# A31G22x register map
Vendor: ABOV Semiconductor Co., Ltd.; Series: A31G22x; File version: 0.2
CPU: CM0PLUS r0p1, little endian, no MPU, no FPU, VTOR, 2 interrupt priority bits
Registers are 32-bit, read-write, reset 0x0 unless marked. A register's access mark holds for its fields unless they carry their own. Offsets are from the block's base; [hi:lo] are bit positions; {n}, {i} and the like mark numbered series.

## DAC — 12-BIT D/A CONVERTER
Base 0x40003450
0x00 DR — D/A Converter Data Register
  [15:0] DACDR — D/A Converter Data (16-bit) The DACDR[15:0] is a binary format.
0x04 BR ro — D/A Converter Buffer Register
  [15:0] DACBR — D/A Converter Buffer Data (16-bit) The DACBR[15:0] is a binary format.
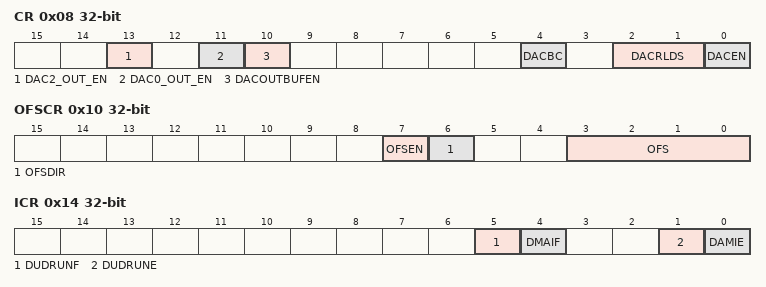
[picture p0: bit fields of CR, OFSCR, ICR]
0x08 CR — D/A Converter Control Register
  [13] DAC2_OUT_EN — Select DAC2_OUT channel for Internal output to DAC_Output of CMP DAC_OUT2 is internally connected to comparator Input
  [11] DAC0_OUT_EN — Select DAC0_OUT channel for DAO(PA6) pin output DAC_OUT0 is connected DAO pin in analog output mode
  [10] DACOUTBUFEN — DAC Output Buffer Selection
  [4] DACBC — D/A Converter Buffer Clear
  [2:1] DACRLDS — D/A Converter Reload Selection. These bits select a reload signal to load data from D/AC data register to buffer.
  [0] DACEN — D/A Converter Enable Bit
0x0C PGSR reset 0x5 — Programmable Gain Control Register
  [3:0] PSG — Programmable Gain Selection
0x10 OFSCR — D/A Converter Offset Control Register
  [7] OFSEN — D/A Converter Offset Control Enable Bit
  [6] OFSDIR — D/A Converter Offset Direction Selection Bit
  [3:0] OFS — D/A Converter Offset Value
0x14 ICR — D/A Converter Interrupt Control Register
  [5] DUDRUNF — DMA under-run interrupt flag
  [4] DMAIF — DMA done received interrupt flag
  [1] DUDRUNE — DMA under-run interrupt enable
  [0] DAMIE — DMA done received interrupt enable

## LCD — LCD DRIVER
Base 0x40005000
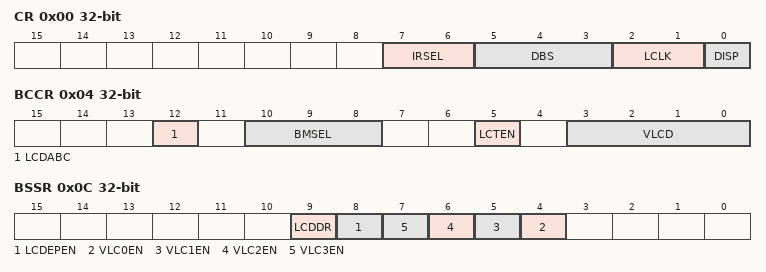
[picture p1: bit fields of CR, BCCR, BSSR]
0x00 CR — LCD Driver Control Register
  [7:6] IRSEL — Internal LCD Bias Driving Resistor bit
    0=RLCD3:105/105/80[kohm]@(1/2)/(1/3)/(1/4) bias; 1=RLCD1: 10/10/10[kohm] @(1/2)/(1/3)/(1/4) bias; 2=RLCD2: 66/66/50[kohm] @(1/2)/(1/3)/(1/4) bias; 3=RLCD4: 320/320/240[kohm] @(1/2)/(1/3)/(1/4) bias
  [5:3] DBS — LCD Duty and Bias Selection bits.
    0=1/8 duty, 1/4 bias; 1=1/6 duty, 1/4 bias; 2=1/5 duty, 1/3 bias; 3=1/4 duty, 1/3 bias; 4=1/3 duty, 1/3 bias; 5=1/3 duty, 1/2 bias
  [2:1] LCLK — LCD Clock Selection bits (When fLCD = 32.768kHz).
    0=128Hz; 1=256Hz; 2=512Hz; 3=1024Hz
  [0] DISP — LCD Display Control bit.
    0=Display off; 1=Normal display on
0x04 BCCR — LCD Automatic Bias and Contrast Control Register
  [12] LCDABC — LCD Automatic Bias Control bit.
    0=LCD automatic bias is off; 1=LCD automatic bias is on
  [10:8] BMSEL — 'Bias Mode A' Time Selection bits. Refer to the figure 'LCD automatic bias control'.
    {v}='Bias Mode A' for {v+1}-clock of fLCD (v=0..7)
  [5] LCTEN — LCD Driver Contrast Control bit.
    0=Disable LCD driver contrast; 1=Enable LCD driver contrast
  [3:0] VLCD — VLC0 Voltage Control when the contrast is enabled.
    0=LVC0 = VDD x 16/31 step; 1=LVC0 = VDD x 16/30 step; 2=LVC0 = VDD x 16/29 step; 3=LVC0 = VDD x 16/28 step; 4=LVC0 = VDD x 16/27 step; 5=LVC0 = VDD x 16/26 step; 6=LVC0 = VDD x 16/25 step; 7=LVC0 = VDD x 16/24 step; 8=LVC0 = VDD x 16/23 step; 9=LVC0 = VDD x 16/22 step; 10=LVC0 = VDD x 16/21 step; 11=LVC0 = VDD x 16/20 step; 12=LVC0 = VDD x 16/19 step; 13=LVC0 = VDD x 16/18 step; 14=LVC0 = VDD x 16/17 step; 15=LVC0 = VDD x 16/16 step
0x0C BSSR — LCD Bias Source Selection Register
  [9] LCDDR — LCD Driving Resistor for Bias Select
    0=Internal LCD driving resistors for bias; 1=External LCD driving resistors for bias
  [8] LCDEPEN — LCD External Bias Path Enable bit
    0=Disable; 1=Enable
  [n+4] VLC{n}EN (n=0..3) — Extenal Bias VLC{n} Enable bit
    0=Disable VLC{n}; 1=Enable VLC{n}
{0x10+i} LCDDR{i} 8-bit (i=0..43) — LCD Display Data Register {i}

## CRC — CYCLIC REDUNDANCY CHECK AND CHECKSUM
Base 0x40000300
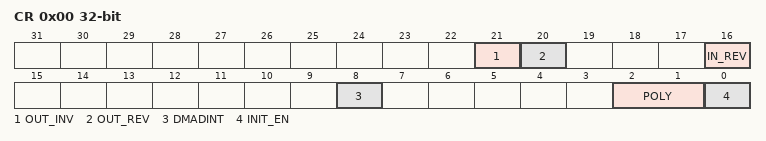
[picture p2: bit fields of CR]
0x00 CR — CRC Control Register
  [21] OUT_INV — CRC output data inversion
    0=Disable Output data inversion; 1=Enable Output data inversion
  [20] OUT_REV — CRC output data reverse
    0=Disable reverse Output data; 1=Enable reverse Output data
  [16] IN_REV — Selects the first data bit to be calculated
    0=LSB (LSB-first); 1=MSB (MSB-first)
  [8] DMADINT — The DMA done interrupt
    0=Disable DMA done interrupt; 1=Enable DMA done interrupt
  [2:1] POLY — Polynomial selection
    0=CRC32 (CRC32 polynomial (0x04C1_1DB7)); 1=CRC16 (CRC16 polynomial (0x8005)); 2=CRC8 (CRC8 polynomial (0x07)); 3=CRC7 (CRC7 Polynomial (0x09))
  [0] INIT_EN wo — CRC initial value
    0=NoEffect; 1=SetInitValue (Applies the initial value register value)
0x04 INIT — CRC Initial Data Register
0x08 IDR 8-bit wo — CRC Input Data Register
  [7:0] INPUT — CRC input data
0x08 ODR ro — CRC Output Data Register
  [31:0] OUTPUT — CRC output data
0x0C SR — CRC Status Register
  [8] DMADINT — DMA done interrupt flag

## TS — TEMPERATURE SENSOR
Base 0x40006300
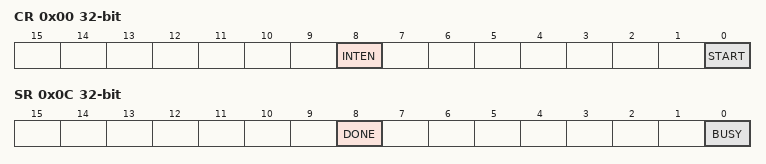
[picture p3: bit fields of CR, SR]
0x00 CR — Temperature Sensor Control Register
  [8] INTEN — TS Interrupt Enable bit
    0=Disable temp sensor interrupt; 1=Enable temp sensor interrupt. When TS_SR flag is set, the interrupt of temp sensor is occurred.
  [0] START — start reference clock counting
    0=Stop reference clock counting; 1=Start, auto clear this bit to ‘0’ after 1 set
0x04 RCCNT — Temperature Sensor Reference Clock Counter Register
  [32:0] RCCV — Reference Clock Counter Initaial Value
0x08 SCCNT ro — Temperature Sensor Sensing Clock Counter Register
  [32:0] SCCV — Temp Sensor Clock Counter value
0x0C SR — Temperature Sensor Status Register
  [8] DONE — Reference Clock Counting Done Flag
    0=Run (Reference clock counter is running.); 1=Done (Reference clock counting is done. When reference clock counter is done, this bit automatically set to ‘1’. This value is cleared by writing ‘1’ to this bit.)
  [0] BUSY ro — The Status of the reference clock counter
    0=Ready (Reference clock counter is ready.); 1=Busy (Reference clock counter is busy. BUSY flag is set ‘1’ during the reference counter is running and automatically clear ‘0’ when reference down-counting is finished.)
